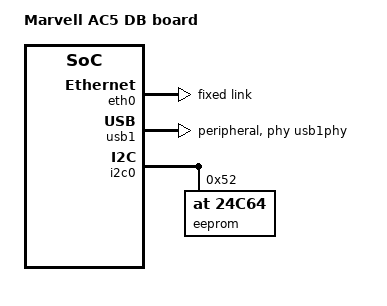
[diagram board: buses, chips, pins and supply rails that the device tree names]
// SPDX-License-Identifier: (GPL-2.0+ OR MIT)
/*
 * Device Tree For AC5_db.
 *
 * Copyright (C) 2021 Marvell
 *
 */
// SPDX-License-Identifier: (GPL-2.0+ OR MIT)
/*
 * Device Tree file for Marvell Alleycat 5 development board
 * This board file supports the B configuration of the board
 */

#include "ac5.dtsi"

/ {
	model = "Marvell AC5 DB board";
};

&eth0 {
	status = "okay";
	fixed-link {
		speed = <1000>;
		full-duplex;
	};
};

&eth1 {
	status = "disabled";
};

&usb1 {
	compatible = "chipidea,usb2";
	phys = <&usb1phy>;
	phy-names = "usb-phy";
	dr_mode = "peripheral";
};

&i2c0 {
	eeprom: eeprom@52 {
		compatible = "at,24c64";
		reg = <0x52>;
	};
};
